# STM32C031xx register map
File version: 1.0
Registers are 32-bit, read-write, reset 0x0 unless marked. A register's access mark holds for its fields unless they carry their own. Offsets are from the block's base; [hi:lo] are bit positions; {n}, {i} and the like mark numbered series.

## WWDG — Window WATCHDOG
Base 0x40002C00
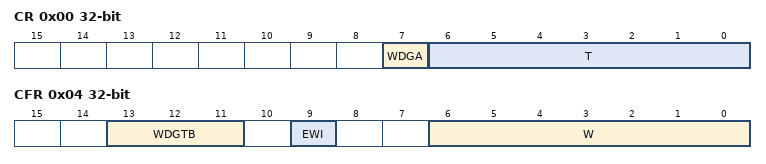
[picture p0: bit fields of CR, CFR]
0x00 CR — WWDG Control register
  [7] WDGA — Activation bit
  [6:0] T — T[6:0] bits (7-Bit counter (MSB to LSB))
0x04 CFR — WWDG Configuration register
  [13:11] WDGTB — WDGTB[2:0] bits (Timer Base)
    0=PRESCALER_1 (WWDG counter clock = (PCLK1/4096)/1); 1=PRESCALER_2 (WWDG counter clock = (PCLK1/4096)/2); 2=PRESCALER_4 (WWDG counter clock = (PCLK1/4096)/4); 3=PRESCALER_8 (WWDG counter clock = (PCLK1/4096)/8); 4=PRESCALER_16 (WWDG counter clock = (PCLK1/4096)/16); 5=PRESCALER_32 (WWDG counter clock = (PCLK1/4096)/32); 6=PRESCALER_64 (WWDG counter clock = (PCLK1/4096)/64); 7=PRESCALER_128 (WWDG counter clock = (PCLK1/4096)/128)
  [9] EWI — Early Wakeup Interrupt
  [6:0] W — W[6:0] bits (7-bit window value)
0x08 SR — WWDG Status register
  [0] EWIF — Early Wakeup Interrupt Flag

## IWDG — Independent WATCHDOG
Base 0x40003000
0x00 KR — IWDG Key register
  [15:0] KEY — Key value (write only, read 0000h)
0x04 PR — IWDG Prescaler register
  [2:0] PR — PR[2:0] (Prescaler divider)
0x08 RLR — IWDG Reload register
  [11:0] RL — Watchdog counter reload value
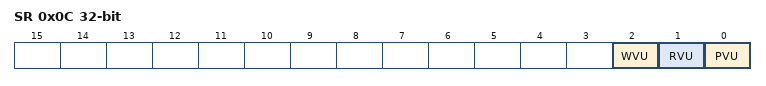
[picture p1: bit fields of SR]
0x0C SR — IWDG Status register
  [2] WVU — Watchdog counter window value update
  [1] RVU — Watchdog counter reload value update
  [0] PVU — Watchdog prescaler value update
0x10 WINR — IWDG Window register
  [11:0] WIN — Watchdog counter window value

## PWR — Power Control
Base 0x40007000
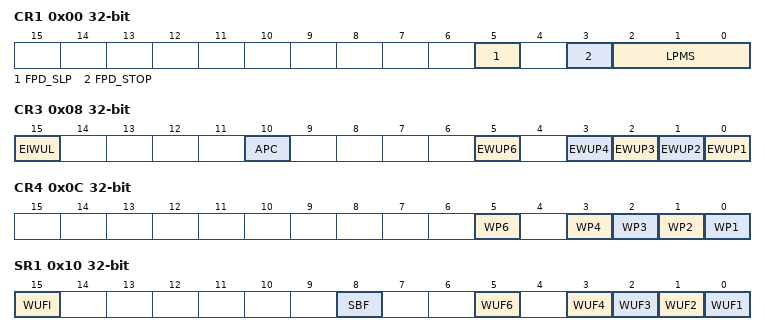
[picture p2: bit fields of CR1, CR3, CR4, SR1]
0x00 CR1 — PWR Power Control Register 1
  [5] FPD_SLP — Flash power down mode during sleep
  [3] FPD_STOP — Flash power down mode during stop
  [2:0] LPMS — Low Power Mode Selection
    0=STOP0; 3=STANDBY; 4=SHUTDOWN
0x08 CR3 — PWR Power Control Register 3
  [15] EIWUL — Enable Internal Wake-up line
  [10] APC — Apply pull-up and pull-down configuration
  [5] EWUP6 — Enable external WKUP pin 6
  [3] EWUP4 — Enable external WKUP pin 4
  [2] EWUP3 — Enable external WKUP pin 3
  [1] EWUP2 — Enable external WKUP pin 2
  [0] EWUP1 — Enable external WKUP Line 1
0x0C CR4 — PWR Power Control Register 4
  [5] WP6 — Wake-Up Line 6 polarity
  [n-1] WP{n} (n=1..4) — Wake-Up Line {n} polarity
0x10 SR1 — PWR Power Status Register 1
  [15] WUFI — Wakeup Flag Internal
  [8] SBF — Standby Flag
  [5] WUF6 — Wakeup Flag 6
  [n-1] WUF{n} (n=1..4) — Wakeup Flag {n}
0x14 SR2 — PWR Power Status Register 2
  [7] FLASH_RDY — Flash Ready
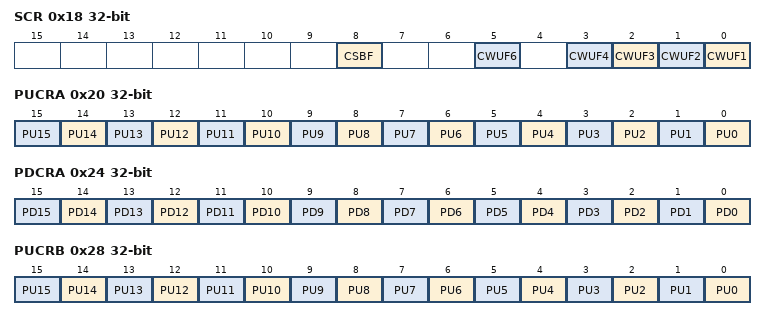
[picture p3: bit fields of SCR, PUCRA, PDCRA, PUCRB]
0x18 SCR — PWR Power Status Clear Register
  [8] CSBF — Clear Standby Flag
  [5] CWUF6 — Clear Wake-up Flag 6
  [n-1] CWUF{n} (n=1..4) — Clear Wake-up Flag {n}
0x20 PUCRA — PWR Pull-Up Control Register of port A
  [n] PU{n} (n=0..15) — Pin PA{n} Pull-Up set
0x24 PDCRA — PWR Pull-Down Control Register of port A
  [n] PD{n} (n=0..15) — Pin PA{n} Pull-Down set
0x28 PUCRB — PWR Pull-Up Control Register of port B
  [n] PU{n} (n=0..15) — Pin PB{n} Pull-Up set
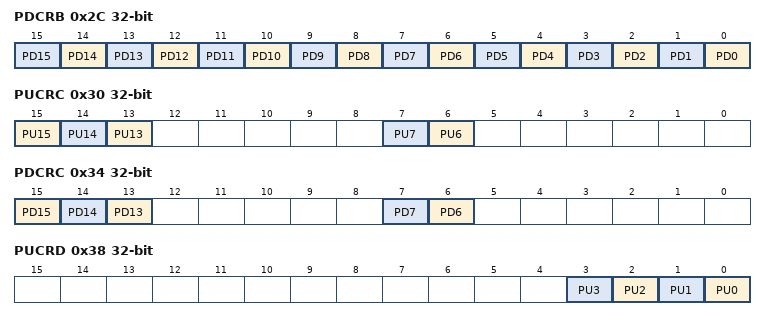
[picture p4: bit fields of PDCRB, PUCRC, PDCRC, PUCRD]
0x2C PDCRB — PWR Pull-Down Control Register of port B
  [n] PD{n} (n=0..15) — Pin PB{n} Pull-Down set
0x30 PUCRC — PWR Pull-Up Control Register of port C
  [15] PU15 — Pin PC15 Pull-Up set
  [14] PU14 — Pin PC14 Pull-Up set
  [13] PU13 — Pin PC13 Pull-Up set
  [7] PU7 — Pin PC7 Pull-Up set
  [6] PU6 — Pin PC6 Pull-Up set
0x34 PDCRC — PWR Pull-Down Control Register of port C
  [15] PD15 — Pin PC15 Pull-Down set
  [14] PD14 — Pin PC14 Pull-Down set
  [13] PD13 — Pin PC13 Pull-Down set
  [7] PD7 — Pin PC7 Pull-Down set
  [6] PD6 — Pin PC6 Pull-Down set
0x38 PUCRD — PWR Pull-Up Control Register of port D
  [n] PU{n} (n=0..3) — Pin PD{n} Pull-Up set
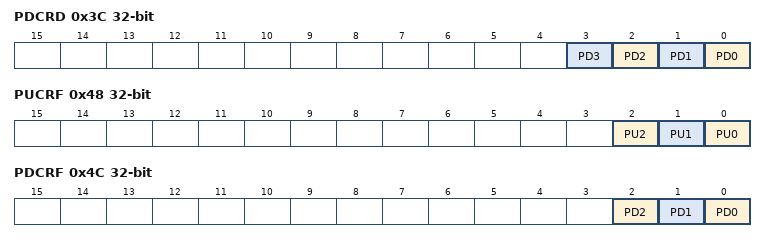
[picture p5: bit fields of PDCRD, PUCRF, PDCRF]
0x3C PDCRD — PWR Pull-Down Control Register of port D
  [n] PD{n} (n=0..3) — Pin PD{n} Pull-Down set
0x48 PUCRF — PWR Pull-Up Control Register of port F
  [2] PU2 — Pin PF2 Pull-Up set
  [1] PU1 — Pin PF1 Pull-Up set
  [0] PU0 — Pin PF0 Pull-Up set
0x4C PDCRF — PWR Pull-Down Control Register of port F
  [2] PD2 — Pin PF2 Pull-Down set
  [1] PD1 — Pin PF1 Pull-Down set
  [0] PD0 — Pin PF0 Pull-Down set
{0x70+4i} BKP{i}R (i=0..3) — Backup register {i}
